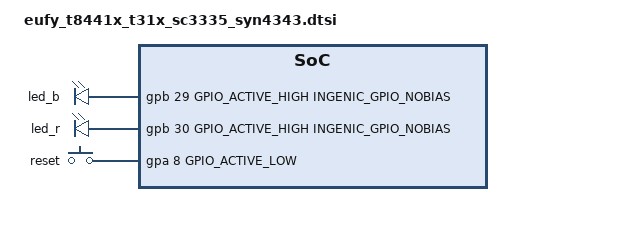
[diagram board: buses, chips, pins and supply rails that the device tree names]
// Eufy E220 T8441X (T31X, SC3335, SYN4343) per-board GPIO definitions.
// Injected into the kernel 4.4+ device tree; ignored on 3.10.

#include <dt-bindings/gpio/gpio.h>
#include <dt-bindings/input/input.h>
#include <dt-bindings/pinctrl/ingenic-pinctrl.h>

/ {
	gpio-leds {
		compatible = "gpio-leds";

		led_b {
			label = "led_b";
			gpios = <&gpb 29 GPIO_ACTIVE_HIGH INGENIC_GPIO_NOBIAS>;
			default-state = "off";
		};

		led_r {
			label = "led_r";
			gpios = <&gpb 30 GPIO_ACTIVE_HIGH INGENIC_GPIO_NOBIAS>;
			default-state = "off";
		};
	};
};

/* Card detect; the family tree carries the reference pin. */
&msc0 {
	ingenic,cd-gpios = <&gpb 26 GPIO_ACTIVE_LOW INGENIC_GPIO_PULLUP>;
};

/ {
	gpio-keys {
		compatible = "gpio-keys";
		label = "gpio-keys";

		reset {
			label = "reset";
			linux,code = <KEY_ENTER>;
			gpios = <&gpa 8 GPIO_ACTIVE_LOW INGENIC_GPIO_PULLUP>;
		};
	};
};
